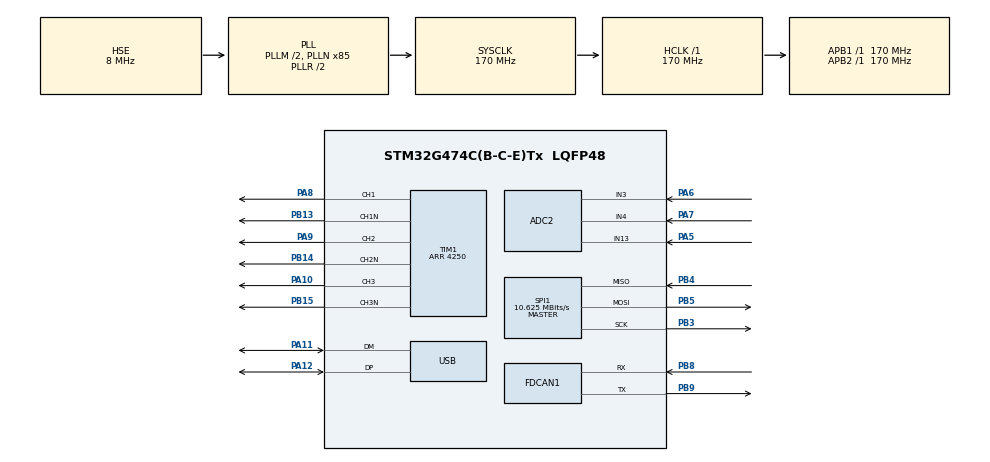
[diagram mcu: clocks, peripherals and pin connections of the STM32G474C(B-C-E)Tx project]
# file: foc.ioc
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ADC2.EnableInjectedConversion=ENABLE
ADC2.EnableRegularConversion=DISABLE
ADC2.ExternalTrigInjecConv=ADC_EXTERNALTRIGINJEC_T1_CC4
ADC2.InjNumberOfConversion=3
ADC2.InjectedChannel-1\#ChannelInjectedConversion=ADC_CHANNEL_3
ADC2.InjectedChannel-2\#ChannelInjectedConversion=ADC_CHANNEL_4
ADC2.InjectedChannel-3\#ChannelInjectedConversion=ADC_CHANNEL_13
ADC2.InjectedOffsetNumber-1\#ChannelInjectedConversion=ADC_OFFSET_NONE
ADC2.InjectedOffsetNumber-2\#ChannelInjectedConversion=ADC_OFFSET_NONE
ADC2.InjectedOffsetNumber-3\#ChannelInjectedConversion=ADC_OFFSET_NONE
ADC2.InjectedRank-1\#ChannelInjectedConversion=1
ADC2.InjectedRank-2\#ChannelInjectedConversion=2
ADC2.InjectedRank-3\#ChannelInjectedConversion=3
ADC2.InjectedSamplingTime-1\#ChannelInjectedConversion=ADC_SAMPLETIME_2CYCLES_5
ADC2.InjectedSamplingTime-2\#ChannelInjectedConversion=ADC_SAMPLETIME_2CYCLES_5
ADC2.InjectedSamplingTime-3\#ChannelInjectedConversion=ADC_SAMPLETIME_2CYCLES_5
ADC2.Rank1_Channel=ADC_CHANNEL_3
ADC2.Rank2_Channel=ADC_CHANNEL_4
ADC2.Rank3_Channel=ADC_CHANNEL_13
FDCAN1.CalculateBaudRateNominal=2125000
FDCAN1.CalculateTimeBitNominal=470
FDCAN1.CalculateTimeQuantumNominal=94.11764705882354
Mcu.Family=STM32G4
Mcu.Name=STM32G474C(B-C-E)Tx
Mcu.Package=LQFP48
NVIC.ADC1_2_IRQn=true\:0\:0\:false\:false\:true\:true\:true\:true
NVIC.PriorityGroup=NVIC_PRIORITYGROUP_4
NVIC.USB_LP_IRQn=true\:0\:0\:false\:false\:true\:false\:true\:true
PA10.Signal=S_TIM1_CH3
PA11.Mode=Device
PA11.Signal=USB_DM
PA12.Mode=Device
PA12.Signal=USB_DP
PA13.Mode=Serial_Wire
PA13.Signal=SYS_JTMS-SWDIO
PA14.Mode=Serial_Wire
PA14.Signal=SYS_JTCK-SWCLK
PA5.Mode=IN13-Single-Ended
PA5.Signal=ADC2_IN13
PA6.Mode=IN3-Single-Ended
PA6.Signal=ADC2_IN3
PA7.Mode=IN4-Single-Ended
PA7.Signal=ADC2_IN4
PA8.Signal=S_TIM1_CH1
PA9.Signal=S_TIM1_CH2
PB13.Mode=PWM Generation1 CH1 CH1N
PB13.Signal=TIM1_CH1N
PB14.Mode=PWM Generation2 CH2 CH2N
PB14.Signal=TIM1_CH2N
PB15.Mode=PWM Generation3 CH3 CH3N
PB15.Signal=TIM1_CH3N
PB3.Mode=Full_Duplex_Master
PB3.Signal=SPI1_SCK
PB4.Mode=Full_Duplex_Master
PB4.Signal=SPI1_MISO
PB5.Mode=Full_Duplex_Master
PB5.Signal=SPI1_MOSI
PB8-BOOT0.Mode=FDCAN_Activate
PB8-BOOT0.Signal=FDCAN1_RX
PB9.Mode=FDCAN_Activate
PB9.Signal=FDCAN1_TX
PF0-OSC_IN.Mode=HSE-External-Oscillator
PF0-OSC_IN.Signal=RCC_OSC_IN
PF1-OSC_OUT.Mode=HSE-External-Oscillator
PF1-OSC_OUT.Signal=RCC_OSC_OUT
ProjectManager.HeapSize=0x200
ProjectManager.StackSize=0x400
ProjectManager.TargetToolchain=STM32CubeIDE
RCC.ADC12Freq_Value=170000000
RCC.ADC345Freq_Value=170000000
RCC.AHBFreq_Value=170000000
RCC.APB1Freq_Value=170000000
RCC.APB1TimFreq_Value=170000000
RCC.APB2Freq_Value=170000000
RCC.APB2TimFreq_Value=170000000
RCC.CK48CLockSelection=RCC_USBCLKSOURCE_HSI48
RCC.CortexFreq_Value=170000000
RCC.EXTERNAL_CLOCK_VALUE=12288000
RCC.EnbaleCSS=true
RCC.HCLKFreq_Value=170000000
RCC.HSI48_VALUE=48000000
RCC.HSI_VALUE=16000000
RCC.LSE_VALUE=32768
RCC.PLLM=RCC_PLLM_DIV2
RCC.PLLN=85
RCC.PLLSourceVirtual=RCC_PLLSOURCE_HSE
RCC.SYSCLKFreq_VALUE=170000000
RCC.SYSCLKSource=RCC_SYSCLKSOURCE_PLLCLK
RCC.USBFreq_Value=48000000
RCC.VCOOutputFreq_Value=340000000
SH.S_TIM1_CH1.0=TIM1_CH1,PWM Generation1 CH1 CH1N
SH.S_TIM1_CH2.0=TIM1_CH2,PWM Generation2 CH2 CH2N
SH.S_TIM1_CH3.0=TIM1_CH3,PWM Generation3 CH3 CH3N
SPI1.BaudRatePrescaler=SPI_BAUDRATEPRESCALER_16
SPI1.CalculateBaudRate=10.625 MBits/s
SPI1.Direction=SPI_DIRECTION_2LINES
SPI1.Mode=SPI_MODE_MASTER
SPI1.VirtualType=VM_MASTER
TIM1.Channel-Output\ Compare4\ No\ Output=TIM_CHANNEL_4
TIM1.Channel-PWM\ Generation1\ CH1\ CH1N=TIM_CHANNEL_1
TIM1.Channel-PWM\ Generation2\ CH2\ CH2N=TIM_CHANNEL_2
TIM1.Channel-PWM\ Generation3\ CH3\ CH3N=TIM_CHANNEL_3
TIM1.CounterMode=TIM_COUNTERMODE_CENTERALIGNED1
TIM1.PeriodNoDither=4250
TIM1.PulseNoDither_4=4200
USB_DEVICE.CLASS_NAME_FS=CDC
USB_DEVICE.VirtualMode=Cdc
USB_DEVICE.VirtualModeFS=Cdc_FS
VP_SYS_VS_DBSignals.Mode=DisableDeadBatterySignals
VP_TIM1_VS_ClockSourceINT.Mode=Internal
VP_TIM1_VS_no_output4.Mode=Output Compare4 No Output
VP_USB_DEVICE_VS_USB_DEVICE_CDC_FS.Mode=CDC_FS
board=custom

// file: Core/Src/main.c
/* USER CODE BEGIN Header */
/**
  ******************************************************************************
  * @file           : main.c
  * @brief          : Main program body
  ******************************************************************************
  * @attention
  *
  * Copyright (c) 2024 STMicroelectronics.
  * All rights reserved.
  *
  * This software is licensed under terms that can be found in the LICENSE file
  * in the root directory of this software component.
  * If no LICENSE file comes with this software, it is provided AS-IS.
  *
  ******************************************************************************
  */
/* USER CODE END Header */
#include "main.h"
#include "adc.h"
#include "fdcan.h"
#include "spi.h"
#include "tim.h"
#include "usb_device.h"
#include "gpio.h"

void SystemClock_Config(void);

int main(void) {

    /* MCU Configuration--------------------------------------------------------*/

    /* Reset of all peripherals, Initializes the Flash interface and the Systick. */
    HAL_Init();

    /* Configure the system clock */
    SystemClock_Config();

    /* Initialize all configured peripherals */
    MX_GPIO_Init();
    MX_FDCAN1_Init();
    MX_SPI1_Init();
    MX_TIM1_Init();
    MX_ADC2_Init();
    MX_USB_Device_Init();
    /* USER CODE BEGIN 2 */
    HAL_ADCEx_InjectedStart(&hadc2);
    __HAL_ADC_ENABLE_IT(&hadc2, ADC_IT_JEOC);

    HAL_TIM_PWM_Start(&htim1, TIM_CHANNEL_1);
    HAL_TIM_PWM_Start(&htim1, TIM_CHANNEL_2);
    HAL_TIM_PWM_Start(&htim1, TIM_CHANNEL_3);
    HAL_TIM_PWM_Start(&htim1, TIM_CHANNEL_4);

    HAL_TIMEx_OCN_Start(&htim1, TIM_CHANNEL_1);
    HAL_TIMEx_OCN_Start(&htim1, TIM_CHANNEL_2);
    HAL_TIMEx_OCN_Start(&htim1, TIM_CHANNEL_3);

    Main();
    /* USER CODE END 2 */

    /* Infinite loop */
    while (1) {

    }
}

void SystemClock_Config(void) {
    RCC_OscInitTypeDef RCC_OscInitStruct = {0};
    RCC_ClkInitTypeDef RCC_ClkInitStruct = {0};

    /** Configure the main internal regulator output voltage
    */
    HAL_PWREx_ControlVoltageScaling(PWR_REGULATOR_VOLTAGE_SCALE1_BOOST);

    /** Initializes the RCC Oscillators according to the specified parameters
    * in the RCC_OscInitTypeDef structure.
    */
    RCC_OscInitStruct.OscillatorType = RCC_OSCILLATORTYPE_HSI48 | RCC_OSCILLATORTYPE_HSE;
    RCC_OscInitStruct.HSEState = RCC_HSE_ON;
    RCC_OscInitStruct.HSI48State = RCC_HSI48_ON;
    RCC_OscInitStruct.PLL.PLLState = RCC_PLL_ON;
    RCC_OscInitStruct.PLL.PLLSource = RCC_PLLSOURCE_HSE;
    RCC_OscInitStruct.PLL.PLLM = RCC_PLLM_DIV2;
    RCC_OscInitStruct.PLL.PLLN = 85;
    RCC_OscInitStruct.PLL.PLLP = RCC_PLLP_DIV2;
    RCC_OscInitStruct.PLL.PLLQ = RCC_PLLQ_DIV2;
    RCC_OscInitStruct.PLL.PLLR = RCC_PLLR_DIV2;
    if (HAL_RCC_OscConfig(&RCC_OscInitStruct) != HAL_OK) {
        Error_Handler();
    }

    /** Initializes the CPU, AHB and APB buses clocks
    */
    RCC_ClkInitStruct.ClockType = RCC_CLOCKTYPE_HCLK | RCC_CLOCKTYPE_SYSCLK
                                  | RCC_CLOCKTYPE_PCLK1 | RCC_CLOCKTYPE_PCLK2;
    RCC_ClkInitStruct.SYSCLKSource = RCC_SYSCLKSOURCE_PLLCLK;
    RCC_ClkInitStruct.AHBCLKDivider = RCC_SYSCLK_DIV1;
    RCC_ClkInitStruct.APB1CLKDivider = RCC_HCLK_DIV1;
    RCC_ClkInitStruct.APB2CLKDivider = RCC_HCLK_DIV1;

    if (HAL_RCC_ClockConfig(&RCC_ClkInitStruct, FLASH_LATENCY_4) != HAL_OK) {
        Error_Handler();
    }

    /** Enables the Clock Security System
    */
    HAL_RCC_EnableCSS();
}

/* USER CODE BEGIN 4 */
void HAL_ADCEx_InjectedConvCpltCallback(ADC_HandleTypeDef *hadc) {
    adc_interrupt(hadc);
}
/* USER CODE END 4 */

void Error_Handler(void) {
    __disable_irq();
    while (1) {
    }
}
